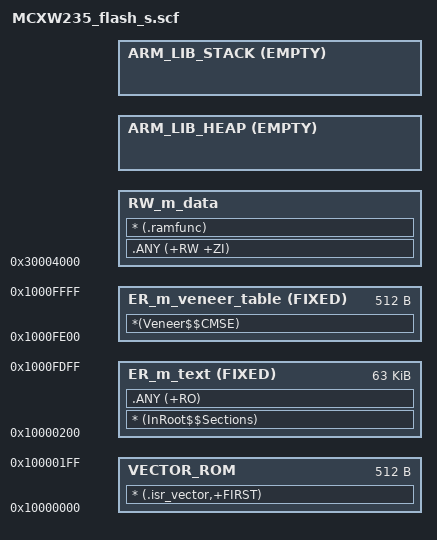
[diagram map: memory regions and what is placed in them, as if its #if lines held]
#!armclang --target=arm-arm-none-eabi -march=armv8-m.main -E -x c
/*
** ###################################################################
**     Processors:          MCXW235AIHNAR
**                          MCXW235AIUKAR
**                          MCXW235BIHNAR
**                          MCXW235BIUKAR
**
**     Compiler:            Keil ARM C/C++ Compiler
**     Reference manual:    MCXW23x User manual Rev. 1.0 - 7 April 2025
**     Version:             rev. 1.0, 2022-03-08
**     Build:               b250819
**
**     Abstract:
**         Linker file for the Keil ARM C/C++ Compiler
**
**     Copyright 2016 Freescale Semiconductor, Inc.
**     Copyright 2016-2025 NXP
**     SPDX-License-Identifier: BSD-3-Clause
**
**     http:                 www.nxp.com
**     mail:                 support@nxp.com
**
** ###################################################################
*/


/* Sizes */
#if (defined(__stack_size__))
  #define Stack_Size                   __stack_size__
#else
  #define Stack_Size                   0x0400
#endif

#if (defined(__heap_size__))
  #define Heap_Size                    __heap_size__
#else
  #define Heap_Size                    0x0400
#endif

#define  m_interrupts_start            0x10000000
#define  m_interrupts_size             0x00000200

#define  m_text_start                  0x10000200
#define  m_text_size                   0x0000FC00

/* NSC veneer table: Keil places Veneer$$CMSE here.
   armlink option --import_cmse_lib_out produces the CMSE import library
   for the NS project to link against. */
#define  m_veneer_table_start          0x1000FE00
#define  m_veneer_table_size           0x00000200

/* Secure RAM: SRAM1 (32 KB), secure alias - identical to MCXW236 */
#define  m_data_start                  0x30004000
#define  m_data_size                   0x00008000

LR_m_text m_interrupts_start m_interrupts_size+m_text_size+m_veneer_table_size {

  VECTOR_ROM m_interrupts_start m_interrupts_size { ; load address = execution address
    * (.isr_vector,+FIRST)
  }

  ER_m_text m_text_start FIXED m_text_size { ; load address = execution address
    * (InRoot$$Sections)
    .ANY (+RO)
  }

  ER_m_veneer_table m_veneer_table_start FIXED m_veneer_table_size { ; NSC veneer table
    *(Veneer$$CMSE)
  }

  RW_m_data m_data_start m_data_size-Stack_Size-Heap_Size { ; RW data
    .ANY (+RW +ZI)
    * (.ramfunc)
  }
  ARM_LIB_HEAP +0 EMPTY Heap_Size {    ; Heap region growing up
  }
  ARM_LIB_STACK m_data_start+m_data_size EMPTY -Stack_Size { ; Stack region growing down
  }

  ScatterAssert(ImageLimit(ARM_LIB_STACK) <= 0x3000C000); /* Check for Secure RAM overflow */
}
